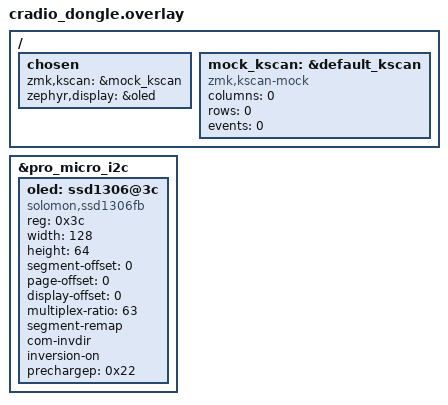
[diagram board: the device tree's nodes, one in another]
/*
 * Copyright (c) 2020 The ZMK Contributors
 *
 * SPDX-License-Identifier: MIT
 * https://github.com/englmaxi/zmk-dongle-display/tree/main
 */

#include "cradio.dtsi"


/ {
    chosen {
        zmk,kscan = &mock_kscan;
        zephyr,display = &oled;
    };

    mock_kscan: &default_kscan {
        compatible = "zmk,kscan-mock";
        columns = <0>;
        rows = <0>;
        events = <0>;
    };
};

&pro_micro_i2c {
    status = "okay";

    oled: ssd1306@3c {
        compatible = "solomon,ssd1306fb";
        reg = <0x3c>;
        width = <128>;
        height = <64>;
        segment-offset = <0>;
        page-offset = <0>;
        display-offset = <0>;
        multiplex-ratio = <63>;
        segment-remap;
        com-invdir;
        inversion-on;
        prechargep = <0x22>;
    };
};
